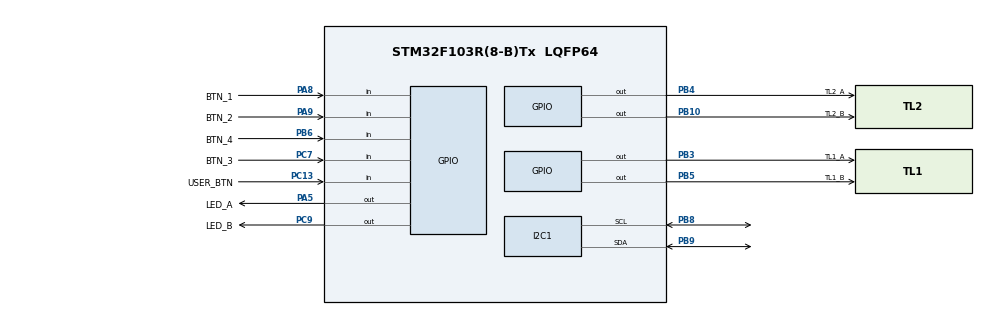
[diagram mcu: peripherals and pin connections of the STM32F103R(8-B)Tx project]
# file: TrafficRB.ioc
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Mcu.Family=STM32F1
Mcu.Name=STM32F103R(8-B)Tx
Mcu.Package=LQFP64
NVIC.PriorityGroup=NVIC_PRIORITYGROUP_4
NVIC.TIM2_IRQn=true\:0\:0\:false\:false\:true\:true\:true
PA13.GPIO_Label=TMS
PA13.Mode=Serial_Wire
PA13.Signal=SYS_JTMS-SWDIO
PA14.GPIO_Label=TCK
PA14.Mode=Serial_Wire
PA14.Signal=SYS_JTCK-SWCLK
PA5.GPIO_Label=LED_A
PA5.Signal=GPIO_Output
PA8.GPIO_Label=BTN_1
PA8.GPIO_PuPd=GPIO_PULLUP
PA8.Signal=GPIO_Input
PA9.GPIO_Label=BTN_2
PA9.GPIO_PuPd=GPIO_PULLUP
PA9.Signal=GPIO_Input
PB10.GPIO_Label=TL2_B
PB10.Signal=GPIO_Output
PB3.GPIO_Label=TL1_A
PB3.Signal=GPIO_Output
PB4.GPIO_Label=TL2_A
PB4.Signal=GPIO_Output
PB5.GPIO_Label=TL1_B
PB5.Signal=GPIO_Output
PB6.GPIO_Label=BTN_4
PB6.GPIO_PuPd=GPIO_PULLUP
PB6.Signal=GPIO_Input
PB8.Mode=I2C
PB8.Signal=I2C1_SCL
PB9.Mode=I2C
PB9.Signal=I2C1_SDA
PC13-TAMPER-RTC.GPIO_Label=USER_BTN
PC13-TAMPER-RTC.GPIO_PuPd=GPIO_PULLUP
PC13-TAMPER-RTC.Signal=GPIO_Input
PC7.GPIO_Label=BTN_3
PC7.GPIO_PuPd=GPIO_PULLUP
PC7.Signal=GPIO_Input
PC9.GPIO_Label=LED_B
PC9.Signal=GPIO_Output
ProjectManager.HeapSize=0x200
ProjectManager.StackSize=0x400
ProjectManager.TargetToolchain=STM32CubeIDE
RCC.APB1Freq_Value=8000000
RCC.APB2Freq_Value=8000000
TIM2.Period=9
TIM2.Prescaler=7999
VP_TIM2_VS_ClockSourceINT.Mode=Internal
board=NUCLEO-F103RB

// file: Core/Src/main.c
/* USER CODE BEGIN Header */
/**
  ******************************************************************************
  * @file           : main.c
  * @brief          : Main program body
  ******************************************************************************
  * @attention
  *
  * <h2><center>&copy; Copyright (c) 2026 STMicroelectronics.
  * All rights reserved.</center></h2>
  *
  * This software component is licensed by ST under BSD 3-Clause license,
  * the "License"; You may not use this file except in compliance with the
  * License. You may obtain a copy of the License at:
  *                        opensource.org/licenses/BSD-3-Clause
  *
  ******************************************************************************
  */
/* USER CODE END Header */
#include "main.h"

/* USER CODE BEGIN Includes */
#include "tasks.h"
#include "bringup.h"
#include "board_config.h"
#include "scheduler.h"

/* USER CODE END Includes */

I2C_HandleTypeDef hi2c1;

TIM_HandleTypeDef htim2;

void SystemClock_Config(void);
static void MX_GPIO_Init(void);
static void MX_TIM2_Init(void);
static void MX_I2C1_Init(void);

int main(void)
{

  /* MCU Configuration--------------------------------------------------------*/

  /* Reset of all peripherals, Initializes the Flash interface and the Systick. */
  HAL_Init();

  /* Configure the system clock */
  SystemClock_Config();

  /* Initialize all configured peripherals */
  MX_GPIO_Init();
  MX_TIM2_Init();
  MX_I2C1_Init();
  /* USER CODE BEGIN 2 */
#if BOARD_BRINGUP
  bringup_start();
#else
  tasks_start();
#endif
  if (HAL_TIM_Base_Start_IT(&htim2) != HAL_OK) Error_Handler();

  /* USER CODE END 2 */

  /* Infinite loop */
  while (1)
  {

    /* USER CODE BEGIN 3 */
    SCH_Dispatch_Tasks();
  }
  /* USER CODE END 3 */
}

void SystemClock_Config(void)
{
  RCC_OscInitTypeDef RCC_OscInitStruct = {0};
  RCC_ClkInitTypeDef RCC_ClkInitStruct = {0};

  /** Initializes the RCC Oscillators according to the specified parameters
  * in the RCC_OscInitTypeDef structure.
  */
  RCC_OscInitStruct.OscillatorType = RCC_OSCILLATORTYPE_HSI;
  RCC_OscInitStruct.HSIState = RCC_HSI_ON;
  RCC_OscInitStruct.HSICalibrationValue = RCC_HSICALIBRATION_DEFAULT;
  RCC_OscInitStruct.PLL.PLLState = RCC_PLL_NONE;
  if (HAL_RCC_OscConfig(&RCC_OscInitStruct) != HAL_OK)
  {
    Error_Handler();
  }
  /** Initializes the CPU, AHB and APB buses clocks
  */
  RCC_ClkInitStruct.ClockType = RCC_CLOCKTYPE_HCLK|RCC_CLOCKTYPE_SYSCLK
                              |RCC_CLOCKTYPE_PCLK1|RCC_CLOCKTYPE_PCLK2;
  RCC_ClkInitStruct.SYSCLKSource = RCC_SYSCLKSOURCE_HSI;
  RCC_ClkInitStruct.AHBCLKDivider = RCC_SYSCLK_DIV1;
  RCC_ClkInitStruct.APB1CLKDivider = RCC_HCLK_DIV1;
  RCC_ClkInitStruct.APB2CLKDivider = RCC_HCLK_DIV1;

  if (HAL_RCC_ClockConfig(&RCC_ClkInitStruct, FLASH_LATENCY_0) != HAL_OK)
  {
    Error_Handler();
  }
}

static void MX_I2C1_Init(void)
{

  hi2c1.Instance = I2C1;
  hi2c1.Init.ClockSpeed = 100000;
  hi2c1.Init.DutyCycle = I2C_DUTYCYCLE_2;
  hi2c1.Init.OwnAddress1 = 0;
  hi2c1.Init.AddressingMode = I2C_ADDRESSINGMODE_7BIT;
  hi2c1.Init.DualAddressMode = I2C_DUALADDRESS_DISABLE;
  hi2c1.Init.OwnAddress2 = 0;
  hi2c1.Init.GeneralCallMode = I2C_GENERALCALL_DISABLE;
  hi2c1.Init.NoStretchMode = I2C_NOSTRETCH_DISABLE;
  if (HAL_I2C_Init(&hi2c1) != HAL_OK)
  {
    Error_Handler();
  }

}

static void MX_TIM2_Init(void)
{

  TIM_ClockConfigTypeDef sClockSourceConfig = {0};
  TIM_MasterConfigTypeDef sMasterConfig = {0};

  htim2.Instance = TIM2;
  htim2.Init.Prescaler = 7999;
  htim2.Init.CounterMode = TIM_COUNTERMODE_UP;
  htim2.Init.Period = 9;
  htim2.Init.ClockDivision = TIM_CLOCKDIVISION_DIV1;
  htim2.Init.AutoReloadPreload = TIM_AUTORELOAD_PRELOAD_DISABLE;
  if (HAL_TIM_Base_Init(&htim2) != HAL_OK)
  {
    Error_Handler();
  }
  sClockSourceConfig.ClockSource = TIM_CLOCKSOURCE_INTERNAL;
  if (HAL_TIM_ConfigClockSource(&htim2, &sClockSourceConfig) != HAL_OK)
  {
    Error_Handler();
  }
  sMasterConfig.MasterOutputTrigger = TIM_TRGO_RESET;
  sMasterConfig.MasterSlaveMode = TIM_MASTERSLAVEMODE_DISABLE;
  if (HAL_TIMEx_MasterConfigSynchronization(&htim2, &sMasterConfig) != HAL_OK)
  {
    Error_Handler();
  }

}

static void MX_GPIO_Init(void)
{
  GPIO_InitTypeDef GPIO_InitStruct = {0};

  /* GPIO Ports Clock Enable */
  __HAL_RCC_GPIOC_CLK_ENABLE();
  __HAL_RCC_GPIOA_CLK_ENABLE();
  __HAL_RCC_GPIOB_CLK_ENABLE();

  /*Configure GPIO pin Output Level */
  HAL_GPIO_WritePin(LED_A_GPIO_Port, LED_A_Pin, GPIO_PIN_RESET);

  /*Configure GPIO pin Output Level */
  HAL_GPIO_WritePin(GPIOB, TL2_B_Pin|TL1_A_Pin|TL2_A_Pin|TL1_B_Pin, GPIO_PIN_RESET);

  /*Configure GPIO pin Output Level */
  HAL_GPIO_WritePin(LED_B_GPIO_Port, LED_B_Pin, GPIO_PIN_RESET);

  /*Configure GPIO pins : USER_BTN_Pin BTN_3_Pin */
  GPIO_InitStruct.Pin = USER_BTN_Pin|BTN_3_Pin;
  GPIO_InitStruct.Mode = GPIO_MODE_INPUT;
  GPIO_InitStruct.Pull = GPIO_PULLUP;
  HAL_GPIO_Init(GPIOC, &GPIO_InitStruct);

  /*Configure GPIO pin : LED_A_Pin */
  GPIO_InitStruct.Pin = LED_A_Pin;
  GPIO_InitStruct.Mode = GPIO_MODE_OUTPUT_PP;
  GPIO_InitStruct.Pull = GPIO_NOPULL;
  GPIO_InitStruct.Speed = GPIO_SPEED_FREQ_LOW;
  HAL_GPIO_Init(LED_A_GPIO_Port, &GPIO_InitStruct);

  /*Configure GPIO pins : TL2_B_Pin TL1_A_Pin TL2_A_Pin TL1_B_Pin */
  GPIO_InitStruct.Pin = TL2_B_Pin|TL1_A_Pin|TL2_A_Pin|TL1_B_Pin;
  GPIO_InitStruct.Mode = GPIO_MODE_OUTPUT_PP;
  GPIO_InitStruct.Pull = GPIO_NOPULL;
  GPIO_InitStruct.Speed = GPIO_SPEED_FREQ_LOW;
  HAL_GPIO_Init(GPIOB, &GPIO_InitStruct);

  /*Configure GPIO pin : LED_B_Pin */
  GPIO_InitStruct.Pin = LED_B_Pin;
  GPIO_InitStruct.Mode = GPIO_MODE_OUTPUT_PP;
  GPIO_InitStruct.Pull = GPIO_NOPULL;
  GPIO_InitStruct.Speed = GPIO_SPEED_FREQ_LOW;
  HAL_GPIO_Init(LED_B_GPIO_Port, &GPIO_InitStruct);

  /*Configure GPIO pins : BTN_1_Pin BTN_2_Pin */
  GPIO_InitStruct.Pin = BTN_1_Pin|BTN_2_Pin;
  GPIO_InitStruct.Mode = GPIO_MODE_INPUT;
  GPIO_InitStruct.Pull = GPIO_PULLUP;
  HAL_GPIO_Init(GPIOA, &GPIO_InitStruct);

  /*Configure GPIO pin : BTN_4_Pin */
  GPIO_InitStruct.Pin = BTN_4_Pin;
  GPIO_InitStruct.Mode = GPIO_MODE_INPUT;
  GPIO_InitStruct.Pull = GPIO_PULLUP;
  HAL_GPIO_Init(BTN_4_GPIO_Port, &GPIO_InitStruct);

}

/* USER CODE BEGIN 4 */
void HAL_TIM_PeriodElapsedCallback(TIM_HandleTypeDef *htim){
  if(htim->Instance == TIM2) SCH_Update();
}

/* USER CODE END 4 */

void Error_Handler(void)
{
  __disable_irq();
  while (1)
  {
  }
}

/************************ (C) COPYRIGHT STMicroelectronics *****END OF FILE****/
